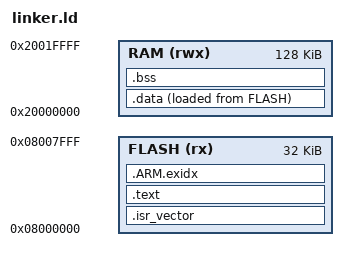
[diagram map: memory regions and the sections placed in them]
ENTRY(Reset_Handler)

MEMORY
{
    /* Sectors 0-1. Sectors 2-4 hold the counter log and the key store
     * and must never be part of the image. */
    FLASH (rx)  : ORIGIN = 0x08000000, LENGTH = 32K
    RAM   (rwx) : ORIGIN = 0x20000000, LENGTH = 128K
}

_estack = ORIGIN(RAM) + LENGTH(RAM);

SECTIONS
{
    .isr_vector :
    {
        KEEP(*(.isr_vector))
    } > FLASH

    .text :
    {
        *(.text*)
        *(.rodata*)
        . = ALIGN(4);
    } > FLASH

    .ARM.exidx :
    {
        *(.ARM.exidx*)
        . = ALIGN(4);
    } > FLASH

    .data :
    {
        . = ALIGN(4);
        _sdata = .;
        *(.data*)
        . = ALIGN(4);
        _edata = .;
    } > RAM AT > FLASH

    _sidata = LOADADDR(.data);

    .bss (NOLOAD) :
    {
        . = ALIGN(4);
        _sbss = .;
        *(.bss*)
        *(COMMON)
        . = ALIGN(4);
        _ebss = .;
    } > RAM
}
